# ATtiny441 device description
Architecture: AVR8; Family: tinyAVR
Registers are 8-bit, access not given, no defined reset value unless marked. A register's access mark holds for its fields unless they carry their own. Offsets are from the block's base; [hi:lo] are bit positions; {n}, {i} and the like mark numbered series.

## TC0 (TC8 module) — Timer/Counter, 8-bit
Instances: TC0 0x00
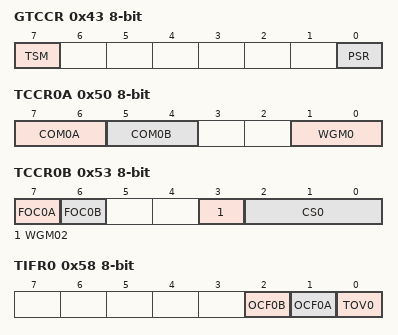
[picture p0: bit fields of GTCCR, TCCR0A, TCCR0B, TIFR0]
0x43 GTCCR — General Timer/Counter Control Register
  [7] TSM — Timer/Counter Synchronization Mode
  [0] PSR — Prescaler Reset Timer/CounterN
0x50 TCCR0A — Timer/Counter Control Register A
  [7:6] COM0A — Compare Match Output A Mode bits
  [5:4] COM0B — Compare Match Output B Mode bits
  [1:0] WGM0 — Waveform Generation Mode bits
0x52 TCNT0 — Timer/Counter0
0x53 TCCR0B — Timer/Counter Control Register B
  [7] FOC0A — Force Output Compare A
  [6] FOC0B — Force Output Compare B
  [3] WGM02 — Waveform Generation Mode bit 2
  [2:0] CS0 — Clock Select bits
    0=No Clock Source (Stopped); 1=Running, No Prescaling; 2=Running, CLK/8; 3=Running, CLK/64; 4=Running, CLK/256; 5=Running, CLK/1024; 6=Running, ExtClk Tx Falling Edge; 7=Running, ExtClk Tx Rising Edge
0x56 OCR0A — Timer/Counter0 Output Compare Register A
0x58 TIFR0 — Timer/Counter0 Interrupt Flag Register
  [2] OCF0B — Timer/Counter0 Output Compare Flag B
  [1] OCF0A — Timer/Counter0 Output Compare Flag A
  [0] TOV0 — Timer/Counter0 Overflow Flag
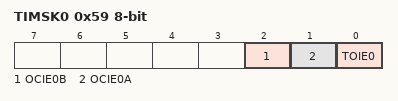
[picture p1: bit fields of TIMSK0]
0x59 TIMSK0 — Timer/Counter Interrupt Mask Register
  [2] OCIE0B — Timer/Counter0 Output Compare Match B Interrupt Enable
  [1] OCIE0A — Timer/Counter0 Output Compare Match A Interrupt Enable
  [0] TOIE0 — Timer/Counter0 Overflow Interrupt Enable
0x5C OCR0B — Timer/Counter0 Output Compare Register B

## EXINT — External Interrupts
Instances: EXINT 0x00
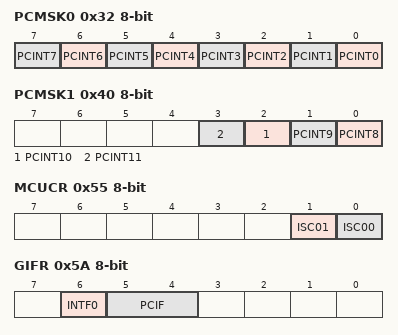
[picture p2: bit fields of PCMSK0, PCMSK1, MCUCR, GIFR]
0x32 PCMSK0 — Pin Change Enable Mask 0
  [n] PCINT{n} (n=0..7) — Pin Change Enable Mask 0 Bit {n}
0x40 PCMSK1 — Pin Change Enable Mask 1
  [n-8] PCINT{n} (n=8..11) — Pin Change Enable Mask 1 Bit {n-8}
0x55 MCUCR — MCU Control Register
  [1] ISC01 — Interrupt Sense Control 0 Bit 1
  [0] ISC00 — Interrupt Sense Control 0 Bit 0
    0=Low Level of INTX; 2=Falling Edge of INTX; 3=Rising Edge of INTX
0x5A GIFR — General Interrupt Flag register
  [6] INTF0 — External Interrupt Flag 0
  [5:4] PCIF — Pin Change Interrupt Flags
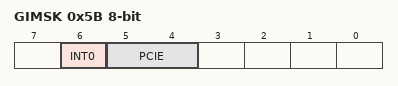
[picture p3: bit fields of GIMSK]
0x5B GIMSK — General Interrupt Mask Register
  [6] INT0 — External Interrupt Request 0 Enable
  [5:4] PCIE — Pin Change Interrupt Enables

## CPU — CPU Registers
Instances: CPU 0x00
Parameters: CORE_VERSION=V2, NEW_INSTRUCTIONS=lpm rd,z+
{0x33+i} GPIOR{i} (i=0..2) — General Purpose I/O Register {i}
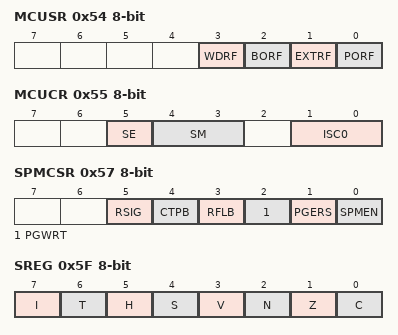
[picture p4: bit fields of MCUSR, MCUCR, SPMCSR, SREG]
0x54 MCUSR — MCU Status Register
  [3] WDRF — Watchdog Reset Flag
  [2] BORF — Brown-out Reset Flag
  [1] EXTRF — External Reset Flag
  [0] PORF — Power-on reset flag
0x55 MCUCR — MCU Control Register
  [5] SE — Sleep Enable
  [4:3] SM — Sleep Mode Select Bits
    0=IDLE; 1=ADC (ADC Noise Reduction (If Available)); 2=PDOWN (Power Down); 3=STDBY (Standby)
  [1:0] ISC0 — Interrupt Sense Control 0 bits
0x57 SPMCSR — Store Program Memory Control and Status Register
  [5] RSIG — Read Device Signature Imprint Table
  [4] CTPB — Clear Temporary Page Buffer
  [3] RFLB — Read Fuse and Lock Bits
  [2] PGWRT — Page Write
  [1] PGERS — Page Erase
  [0] SPMEN — Store program Memory Enable
0x5D SP 16-bit bits used 10:0 — Stack Pointer
0x5F SREG — Status Register
  [7] I — Global Interrupt Enable
  [6] T — Bit Copy Storage
  [5] H — Half Carry Flag
  [4] S — Sign Bit
  [3] V — Two's Complement Overflow Flag
  [2] N — Negative Flag
  [1] Z — Zero Flag
  [0] C — Carry Flag
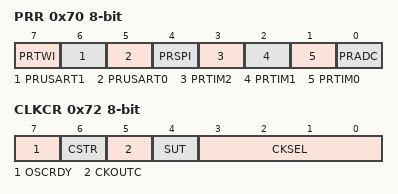
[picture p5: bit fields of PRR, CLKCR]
0x70 PRR — Power Reduction Register
  [7] PRTWI — Power Reduction TWI
  [6] PRUSART1 — Power Reduction USART1
  [5] PRUSART0 — Power Reduction USART0
  [4] PRSPI — Power Reduction SPI
  [3] PRTIM2 — Power Reduction Timer/Counter2
  [2] PRTIM1 — Power Reduction Timer/Counter1
  [1] PRTIM0 — Power Reduction Timer/Counter0
  [0] PRADC — Power Reduction ADC
0x71 CCP — Configuration Change Protection
0x72 CLKCR — Clock Control Register
  [7] OSCRDY — Oscillator Ready
  [6] CSTR — Clock Switch Trigger
  [5] CKOUTC — Clock Output (Copy). Active low.
  [4] SUT — Start-up Time
  [3:0] CKSEL — Clock Select Bits
0x73 CLKPR — Clock Prescale Register
  [3:0] CLKPS — Clock Prescaler Select Bits
    0=1; 1=2; 2=4; 3=8; 4=16; 5=32; 6=64; 7=128; 8=256
0x74 OSCCAL0 — Oscillator Calibration Register 8MHz
0x75 OSCTCAL0A — Oscillator Temperature Calibration Register A
0x76 OSCTCAL0B — Oscillator Temperature Calibration Register B
0x77 OSCCAL1 bits used 1:0 — Oscillator Calibration Register 32kHz
Value list OSCCAL_VALUE_ADDRESSES: 0=8_0_MHz; 3=32_kHz

## TOCPM — Timer/Counter Output Compare Pin
Instances: TOCPM 0x00
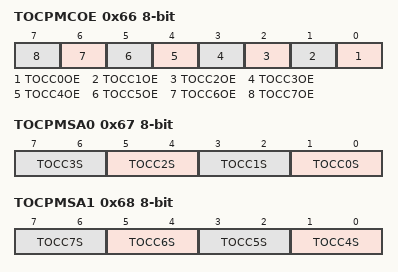
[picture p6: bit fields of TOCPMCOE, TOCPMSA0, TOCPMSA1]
0x66 TOCPMCOE — Timer Output Compare Pin Mux Channel Output Enable
  [n] TOCC{n}OE (n=0..7) — Timer Output Compare Channel {n} Output Enable
0x67 TOCPMSA0 — Timer Output Compare Pin Mux Selection 0
  [2n+1:2n] TOCC{n}S (n=0..3) — Timer Output Compare Channel {n} Selection Bits
0x68 TOCPMSA1 — Timer Output Compare Pin Mux Selection 1
  [2n-7:2n-8] TOCC{n}S (n=4..7) — Timer Output Compare Channel {n} Selection Bits

## SPI — Serial Peripheral Interface
Instances: SPI 0x00
0x65 REMAP — Remap Port Pins
  [1] SPIMAP — SPI Pin Mapping
0xB0 SPDR — SPI Data Register
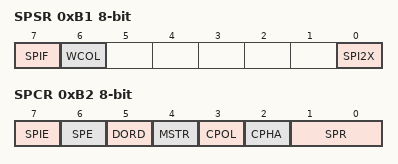
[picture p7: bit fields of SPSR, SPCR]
0xB1 SPSR — SPI Status Register
  [7] SPIF — SPI Interrupt Flag
  [6] WCOL — Write Collision Flag
  [0] SPI2X — Double SPI Speed Bit
0xB2 SPCR — SPI Control Register
  [7] SPIE — SPI Interrupt Enable
  [6] SPE — SPI Enable
  [5] DORD — Data Order
  [4] MSTR — Master/Slave Select
  [3] CPOL — Clock polarity
  [2] CPHA — Clock Phase
  [1:0] SPR — SPI Clock Rate Selects
    0=fcl/4; 1=fcl/16; 2=fcl/64; 3=fcl/128
